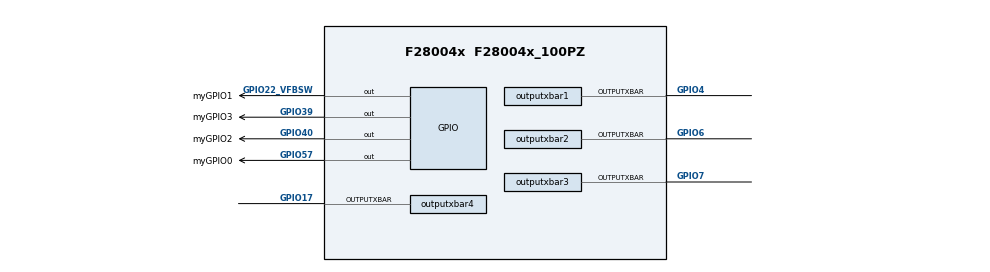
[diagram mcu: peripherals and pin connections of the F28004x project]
/**
 * @cliArgs --device "F28004x" --package "F28004x_100PZ" --part "F28004x_100PZ" --product "C2000WARE@3.00.00.00"
 * @versions {"data":"2021031521","timestamp":"2021031521","tool":"1.8.0+1863","templates":null}
 */
scripting.excludeFromBuild("pinmux.csv");
scripting.excludeFromBuild("clb.dot");
scripting.excludeFromBuild("clb_sim.cpp");

/**
 * Import the modules used in this configuration.
 */
const clb         = scripting.addModule("/driverlib/clb.js", {}, false);
const clb1        = clb.addInstance();
const clb2        = clb.addInstance();
const clb3        = clb.addInstance();
const clb4        = clb.addInstance();
const clbxbar     = scripting.addModule("/driverlib/clbxbar.js", {}, false);
const clbxbar1    = clbxbar.addInstance();
const clbxbar2    = clbxbar.addInstance();
const clbxbar3    = clbxbar.addInstance();
const clbxbar4    = clbxbar.addInstance();
const clbxbar5    = clbxbar.addInstance();
const clbxbar6    = clbxbar.addInstance();
const clbxbar7    = clbxbar.addInstance();
const clbxbar8    = clbxbar.addInstance();
const gpio        = scripting.addModule("/driverlib/gpio.js", {}, false);
const gpio1       = gpio.addInstance();
const gpio2       = gpio.addInstance();
const gpio3       = gpio.addInstance();
const gpio4       = gpio.addInstance();
const inputxbar   = scripting.addModule("/driverlib/inputxbar.js", {}, false);
const inputxbar1  = inputxbar.addInstance();
const outputxbar  = scripting.addModule("/driverlib/outputxbar.js", {}, false);
const outputxbar1 = outputxbar.addInstance();
const outputxbar2 = outputxbar.addInstance();
const outputxbar3 = outputxbar.addInstance();
const outputxbar4 = outputxbar.addInstance();
const TILE        = scripting.addModule("/utilities/clb_tool/clb_syscfg/source/TILE");
const TILE1       = TILE.addInstance();
const TILE2       = TILE.addInstance();
const TILE3       = TILE.addInstance();
const TILE4       = TILE.addInstance();

/**
 * Write custom configuration values to the imported modules.
 */
clb1.inputsUsed          = ["CLB_IN0","CLB_IN1"];
clb1.inputTypeCLB_IN0    = "GLOBAL";
clb1.globalConfigCLB_IN0 = "CLB_GLOBAL_IN_MUX_CLB_AUXSIG0";
clb1.inputTypeCLB_IN1    = "GLOBAL";
clb1.globalConfigCLB_IN1 = "CLB_GLOBAL_IN_MUX_CLB_AUXSIG1";
clb1.$name               = "myCLB1";

clb2.clbBase             = "CLB2_BASE";
clb2.inputsUsed          = ["CLB_IN0","CLB_IN1"];
clb2.inputTypeCLB_IN0    = "GLOBAL";
clb2.globalConfigCLB_IN0 = "CLB_GLOBAL_IN_MUX_CLB_AUXSIG2";
clb2.inputTypeCLB_IN1    = "GLOBAL";
clb2.globalConfigCLB_IN1 = "CLB_GLOBAL_IN_MUX_CLB_AUXSIG3";
clb2.$name               = "myCLB2";

clb3.clbBase             = "CLB3_BASE";
clb3.inputsUsed          = ["CLB_IN0","CLB_IN1"];
clb3.inputTypeCLB_IN0    = "GLOBAL";
clb3.globalConfigCLB_IN0 = "CLB_GLOBAL_IN_MUX_CLB_AUXSIG4";
clb3.inputTypeCLB_IN1    = "GLOBAL";
clb3.globalConfigCLB_IN1 = "CLB_GLOBAL_IN_MUX_CLB_AUXSIG5";
clb3.$name               = "myCLB3";

clb4.clbBase             = "CLB4_BASE";
clb4.inputsUsed          = ["CLB_IN0","CLB_IN1"];
clb4.inputTypeCLB_IN0    = "GLOBAL";
clb4.globalConfigCLB_IN0 = "CLB_GLOBAL_IN_MUX_CLB_AUXSIG6";
clb4.inputTypeCLB_IN1    = "GLOBAL";
clb4.globalConfigCLB_IN1 = "CLB_GLOBAL_IN_MUX_CLB_AUXSIG7";
clb4.$name               = "myCLB4";

clbxbar1.$name     = "myCLBXBAR0";
clbxbar1.muxesUsed = ["XBAR_MUX00"];

clbxbar2.$name      = "myCLBXBAR1";
clbxbar2.auxInput   = "XBAR_AUXSIG1";
clbxbar2.muxesUsed  = ["XBAR_MUX01"];
clbxbar2.mux1Config = "XBAR_CLB_MUX01_INPUTXBAR1";

clbxbar3.$name     = "myCLBXBAR2";
clbxbar3.auxInput  = "XBAR_AUXSIG2";
clbxbar3.muxesUsed = ["XBAR_MUX02"];

clbxbar4.$name      = "myCLBXBAR3";
clbxbar4.auxInput   = "XBAR_AUXSIG3";
clbxbar4.muxesUsed  = ["XBAR_MUX03"];
clbxbar4.mux3Config = "XBAR_CLB_MUX03_INPUTXBAR2";

clbxbar5.$name     = "myCLBXBAR4";
clbxbar5.auxInput  = "XBAR_AUXSIG4";
clbxbar5.muxesUsed = ["XBAR_MUX08"];

clbxbar6.$name      = "myCLBXBAR5";
clbxbar6.auxInput   = "XBAR_AUXSIG5";
clbxbar6.muxesUsed  = ["XBAR_MUX09"];
clbxbar6.mux9Config = "XBAR_CLB_MUX09_INPUTXBAR5";

clbxbar7.$name     = "myCLBXBAR6";
clbxbar7.auxInput  = "XBAR_AUXSIG6";
clbxbar7.muxesUsed = ["XBAR_MUX10"];

clbxbar8.$name       = "myCLBXBAR7";
clbxbar8.auxInput    = "XBAR_AUXSIG7";
clbxbar8.muxesUsed   = ["XBAR_MUX11"];
clbxbar8.mux11Config = "XBAR_CLB_MUX11_INPUTXBAR6";

gpio1.$name           = "myGPIO0";
gpio1.gpioPin.$assign = "GPIO57";

gpio2.$name           = "myGPIO1";
gpio2.gpioPin.$assign = "GPIO22_VFBSW";

gpio3.$name           = "myGPIO2";
gpio3.gpioPin.$assign = "GPIO40";

gpio4.$name           = "myGPIO3";
gpio4.gpioPin.$assign = "GPIO39";

inputxbar1.$name          = "myINPUTXBAR";
inputxbar1.inputxbar2Gpio = "GPIO22";
inputxbar1.inputxbar5Gpio = "GPIO40";
inputxbar1.inputxbar6Gpio = "GPIO39";
inputxbar1.inputsUsed     = ["inputxbar1Gpio","inputxbar2Gpio","inputxbar5Gpio","inputxbar6Gpio"];
inputxbar1.inputxbar1Gpio = "GPIO57";

outputxbar1.$name                            = "myOUTPUTXBAR0";
outputxbar1.muxesUsed                        = ["XBAR_MUX01"];
outputxbar1.mux1Config                       = "XBAR_OUT_MUX01_CLB1_OUT4";
outputxbar1.outputxbar.$assign               = "OUTPUTXBAR3";
outputxbar1.outputxbar.outputxbarPin.$assign = "GPIO4";

outputxbar2.$name                            = "myOUTPUTXBAR1";
outputxbar2.muxesUsed                        = ["XBAR_MUX05"];
outputxbar2.mux5Config                       = "XBAR_OUT_MUX05_CLB2_OUT4";
outputxbar2.outputxbar.$assign               = "OUTPUTXBAR4";
outputxbar2.outputxbar.outputxbarPin.$assign = "GPIO6";

outputxbar3.$name                            = "myOUTPUTXBAR2";
outputxbar3.muxesUsed                        = ["XBAR_MUX09"];
outputxbar3.mux9Config                       = "XBAR_OUT_MUX09_CLB3_OUT4";
outputxbar3.outputxbar.$assign               = "OUTPUTXBAR5";
outputxbar3.outputxbar.outputxbarPin.$assign = "GPIO7";

outputxbar4.$name                            = "myOUTPUTXBAR3";
outputxbar4.muxesUsed                        = ["XBAR_MUX13"];
outputxbar4.mux13Config                      = "XBAR_OUT_MUX13_CLB4_OUT4";
outputxbar4.outputxbar.$assign               = "OUTPUTXBAR8";
outputxbar4.outputxbar.outputxbarPin.$assign = "GPIO17";

TILE.clock_period = 10;
TILE.sim_duration = 100000;

TILE1.$name                     = "TILE0";
TILE1.BOUNDARY.$name            = "BOUNDARY0";
TILE1.BOUNDARY.in_duty1         = 50;
TILE1.BOUNDARY.in_period1       = 100;
TILE1.BOUNDARY.in_repeat_count0 = 50;
TILE1.BOUNDARY.in_repeat_count3 = 1;
TILE1.BOUNDARY.in_repeat_count1 = 1000;
TILE1.BOUNDARY.in_duty0         = 20;
TILE1.BOUNDARY.in_period0       = 40;
TILE1.LUT_0.$name               = "LUT_0";
TILE1.LUT_0.i0                  = "BOUNDARY.in0";
TILE1.LUT_0.i1                  = "BOUNDARY.in1";
TILE1.LUT_0.eqn                 = "i0 & i1";
TILE1.LUT_1.$name               = "LUT_1";
TILE1.LUT_2.$name               = "LUT_2";
TILE1.FSM_0.$name               = "FSM_0";
TILE1.FSM_1.$name               = "FSM_1";
TILE1.FSM_2.$name               = "FSM_2";
TILE1.COUNTER_0.$name           = "COUNTER_0";
TILE1.COUNTER_1.$name           = "COUNTER_1";
TILE1.COUNTER_2.$name           = "COUNTER_2";
TILE1.OUTLUT_0.$name            = "OUTLUT_0";
TILE1.OUTLUT_1.$name            = "OUTLUT_1";
TILE1.OUTLUT_2.$name            = "OUTLUT_2";
TILE1.OUTLUT_3.$name            = "OUTLUT_3";
TILE1.OUTLUT_4.$name            = "OUTLUT_4";
TILE1.OUTLUT_4.i0               = "LUT_0.OUT";
TILE1.OUTLUT_4.eqn              = "i0";
TILE1.OUTLUT_5.$name            = "OUTLUT_5";
TILE1.OUTLUT_6.$name            = "OUTLUT_6";
TILE1.OUTLUT_7.$name            = "OUTLUT_7";
TILE1.HLC.$name                 = "HLC_0";
TILE1.HLC.program0.$name        = "HLCP_0";
TILE1.HLC.program1.$name        = "HLCP_1";
TILE1.HLC.program2.$name        = "HLCP_2";
TILE1.HLC.program3.$name        = "HLCP_3";
TILE1.AOC_0.$name               = "AOC_0";
TILE1.AOC_1.$name               = "AOC_1";
TILE1.AOC_2.$name               = "AOC_2";
TILE1.AOC_3.$name               = "AOC_3";
TILE1.AOC_4.$name               = "AOC_4";
TILE1.AOC_5.$name               = "AOC_5";
TILE1.AOC_6.$name               = "AOC_6";
TILE1.AOC_7.$name               = "AOC_7";

TILE2.$name              = "TILE1";
TILE2.BOUNDARY.$name     = "BOUNDARY1";
TILE2.LUT_0.$name        = "LUT_3";
TILE2.LUT_0.eqn          = "i0 & i1";
TILE2.LUT_0.i0           = "BOUNDARY.in0";
TILE2.LUT_0.i1           = "BOUNDARY.in1";
TILE2.LUT_1.$name        = "LUT_4";
TILE2.LUT_2.$name        = "LUT_5";
TILE2.FSM_0.$name        = "FSM_3";
TILE2.FSM_1.$name        = "FSM_4";
TILE2.FSM_2.$name        = "FSM_5";
TILE2.COUNTER_0.$name    = "COUNTER_3";
TILE2.COUNTER_1.$name    = "COUNTER_4";
TILE2.COUNTER_2.$name    = "COUNTER_5";
TILE2.OUTLUT_0.$name     = "OUTLUT_8";
TILE2.OUTLUT_1.$name     = "OUTLUT_9";
TILE2.OUTLUT_2.$name     = "OUTLUT_10";
TILE2.OUTLUT_3.$name     = "OUTLUT_11";
TILE2.OUTLUT_4.$name     = "OUTLUT_12";
TILE2.OUTLUT_4.i0        = "LUT_0.OUT";
TILE2.OUTLUT_4.eqn       = "i0";
TILE2.OUTLUT_5.$name     = "OUTLUT_13";
TILE2.OUTLUT_6.$name     = "OUTLUT_14";
TILE2.OUTLUT_7.$name     = "OUTLUT_15";
TILE2.HLC.$name          = "HLC_1";
TILE2.HLC.program0.$name = "HLCP_4";
TILE2.HLC.program1.$name = "HLCP_5";
TILE2.HLC.program2.$name = "HLCP_6";
TILE2.HLC.program3.$name = "HLCP_7";
TILE2.AOC_0.$name        = "AOC_8";
TILE2.AOC_1.$name        = "AOC_9";
TILE2.AOC_2.$name        = "AOC_10";
TILE2.AOC_3.$name        = "AOC_11";
TILE2.AOC_4.$name        = "AOC_12";
TILE2.AOC_5.$name        = "AOC_13";
TILE2.AOC_6.$name        = "AOC_14";
TILE2.AOC_7.$name        = "AOC_15";

TILE3.$name              = "TILE2";
TILE3.BOUNDARY.$name     = "BOUNDARY2";
TILE3.LUT_0.$name        = "LUT_6";
TILE3.LUT_0.i0           = "BOUNDARY.in0";
TILE3.LUT_0.i1           = "BOUNDARY.in1";
TILE3.LUT_0.eqn          = "i0 & i1";
TILE3.LUT_1.$name        = "LUT_7";
TILE3.LUT_2.$name        = "LUT_8";
TILE3.FSM_0.$name        = "FSM_6";
TILE3.FSM_1.$name        = "FSM_7";
TILE3.FSM_2.$name        = "FSM_8";
TILE3.COUNTER_0.$name    = "COUNTER_6";
TILE3.COUNTER_1.$name    = "COUNTER_7";
TILE3.COUNTER_2.$name    = "COUNTER_8";
TILE3.OUTLUT_0.$name     = "OUTLUT_16";
TILE3.OUTLUT_1.$name     = "OUTLUT_17";
TILE3.OUTLUT_2.$name     = "OUTLUT_18";
TILE3.OUTLUT_3.$name     = "OUTLUT_19";
TILE3.OUTLUT_4.$name     = "OUTLUT_20";
TILE3.OUTLUT_4.i0        = "LUT_0.OUT";
TILE3.OUTLUT_4.eqn       = "i0";
TILE3.OUTLUT_5.$name     = "OUTLUT_21";
TILE3.OUTLUT_6.$name     = "OUTLUT_22";
TILE3.OUTLUT_7.$name     = "OUTLUT_23";
TILE3.HLC.$name          = "HLC_2";
TILE3.HLC.program0.$name = "HLCP_8";
TILE3.HLC.program1.$name = "HLCP_9";
TILE3.HLC.program2.$name = "HLCP_10";
TILE3.HLC.program3.$name = "HLCP_11";
TILE3.AOC_0.$name        = "AOC_16";
TILE3.AOC_1.$name        = "AOC_17";
TILE3.AOC_2.$name        = "AOC_18";
TILE3.AOC_3.$name        = "AOC_19";
TILE3.AOC_4.$name        = "AOC_20";
TILE3.AOC_5.$name        = "AOC_21";
TILE3.AOC_6.$name        = "AOC_22";
TILE3.AOC_7.$name        = "AOC_23";

TILE4.$name              = "TILE3";
TILE4.BOUNDARY.$name     = "BOUNDARY3";
TILE4.LUT_0.$name        = "LUT_9";
TILE4.LUT_0.i0           = "BOUNDARY.in0";
TILE4.LUT_0.i1           = "BOUNDARY.in1";
TILE4.LUT_0.eqn          = "i0 & i1";
TILE4.LUT_1.$name        = "LUT_10";
TILE4.LUT_2.$name        = "LUT_11";
TILE4.FSM_0.$name        = "FSM_9";
TILE4.FSM_1.$name        = "FSM_10";
TILE4.FSM_2.$name        = "FSM_11";
TILE4.COUNTER_0.$name    = "COUNTER_9";
TILE4.COUNTER_1.$name    = "COUNTER_10";
TILE4.COUNTER_2.$name    = "COUNTER_11";
TILE4.OUTLUT_0.$name     = "OUTLUT_24";
TILE4.OUTLUT_1.$name     = "OUTLUT_25";
TILE4.OUTLUT_2.$name     = "OUTLUT_26";
TILE4.OUTLUT_3.$name     = "OUTLUT_27";
TILE4.OUTLUT_4.$name     = "OUTLUT_28";
TILE4.OUTLUT_4.i0        = "LUT_0.OUT";
TILE4.OUTLUT_4.eqn       = "i0";
TILE4.OUTLUT_5.$name     = "OUTLUT_29";
TILE4.OUTLUT_6.$name     = "OUTLUT_30";
TILE4.OUTLUT_7.$name     = "OUTLUT_31";
TILE4.HLC.$name          = "HLC_3";
TILE4.HLC.program0.$name = "HLCP_12";
TILE4.HLC.program1.$name = "HLCP_13";
TILE4.HLC.program2.$name = "HLCP_14";
TILE4.HLC.program3.$name = "HLCP_15";
TILE4.AOC_0.$name        = "AOC_24";
TILE4.AOC_1.$name        = "AOC_25";
TILE4.AOC_2.$name        = "AOC_26";
TILE4.AOC_3.$name        = "AOC_27";
TILE4.AOC_4.$name        = "AOC_28";
TILE4.AOC_5.$name        = "AOC_29";
TILE4.AOC_6.$name        = "AOC_30";
TILE4.AOC_7.$name        = "AOC_31";
